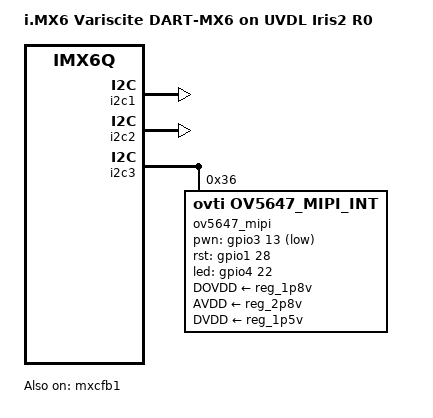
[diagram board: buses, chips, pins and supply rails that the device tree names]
/*
 * Copyright (C) 2015-2017 Variscite Ltd.
 * Copyright (C) 2015-2017 Voipac.
 *
 * The code contained herein is licensed under the GNU General Public
 * License. You may obtain a copy of the GNU General Public License
 * Version 2 or later at the following locations:
 *
 * http://www.opensource.org/licenses/gpl-license.html
 * http://www.gnu.org/copyleft/gpl.html
 */

/dts-v1/;

#include "imx6q.dtsi"
#include "imx6qdl-dart-iris2.dtsi"

/ {
	model = "i.MX6 Variscite DART-MX6 on UVDL Iris2 R0";
	compatible = "fsl,imx6q-dart-iris2", "fsl,imx6q";
};

&i2c1 {
	status = "okay";
};

&i2c2 {
	status = "okay";
};

&i2c3 {
	/* Raspberry Pi camera rev 1.3 */
	ov5647_mipi: ov5647_mipi@36 {
		compatible = "ovti,ov5647_mipi_int";
		reg = <0x36>;
		/* Pi camera has its own 25MHz clock. */
		clocks = <&clks IMX6QDL_CLK_DUMMY>;
		clock-names = "csi_mclk";
		DOVDD-supply = <&reg_1p8v>;
		AVDD-supply = <&reg_2p8v>;
		DVDD-supply = <&reg_1p5v>;
		pwn-gpios = <&gpio3 13 1>;    /* NB: matches DT6C but this is internal to DART-MX6 */
		rst-gpios = <&gpio1 28 0>;    /* Use USB_ETH_PWR_EN to cycle +3V3_USB when detecting camera */
		led-gpios = <&gpio4 22 GPIO_ACTIVE_HIGH>;
		csi_id = <1>;
		mclk = <25000000>;
		mclk_source = <0>;
		pinctrl-names = "default";
		pinctrl-0 = <&pinctrl_ov5647_mipi>;
	};
};

&ldb {
	status = "disabled";
};

&mxcfb1 {
	status = "okay";
};

&mxcfb2 {
	status = "disabled";
};

&mxcfb3 {
	status = "disabled";
};

&mxcfb4 {
	status = "disabled";
};
